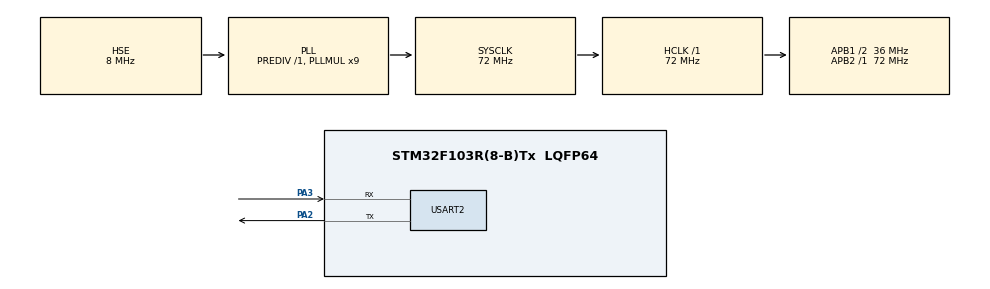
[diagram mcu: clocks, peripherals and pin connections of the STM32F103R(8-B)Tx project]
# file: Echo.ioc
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Mcu.Family=STM32F1
Mcu.Name=STM32F103R(8-B)Tx
Mcu.Package=LQFP64
NVIC.PriorityGroup=NVIC_PRIORITYGROUP_4
PA13.Mode=Serial_Wire
PA13.Signal=SYS_JTMS-SWDIO
PA14.Mode=Serial_Wire
PA14.Signal=SYS_JTCK-SWCLK
PA2.Mode=Asynchronous
PA2.Signal=USART2_TX
PA3.Mode=Asynchronous
PA3.Signal=USART2_RX
PD0-OSC_IN.Mode=HSE-External-Oscillator
PD0-OSC_IN.Signal=RCC_OSC_IN
PD1-OSC_OUT.Mode=HSE-External-Oscillator
PD1-OSC_OUT.Signal=RCC_OSC_OUT
ProjectManager.HeapSize=0x200
ProjectManager.StackSize=0x400
ProjectManager.TargetToolchain=Makefile
RCC.AHBFreq_Value=72000000
RCC.APB1CLKDivider=RCC_HCLK_DIV2
RCC.APB1Freq_Value=36000000
RCC.APB1TimFreq_Value=72000000
RCC.APB2Freq_Value=72000000
RCC.APB2TimFreq_Value=72000000
RCC.HCLKFreq_Value=72000000
RCC.PLLMUL=RCC_PLL_MUL9
RCC.PLLSourceVirtual=RCC_PLLSOURCE_HSE
RCC.SYSCLKFreq_VALUE=72000000
RCC.SYSCLKSource=RCC_SYSCLKSOURCE_PLLCLK
RCC.USBFreq_Value=72000000
USART2.VirtualMode=VM_ASYNC
board=custom

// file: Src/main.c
/* USER CODE BEGIN Header */
/**
  ******************************************************************************
  * @file           : main.c
  * @brief          : Main program body
  ******************************************************************************
  * @attention
  *
  * <h2><center>&copy; Copyright (c) 2020 STMicroelectronics.
  * All rights reserved.</center></h2>
  *
  * This software component is licensed by ST under BSD 3-Clause license,
  * the "License"; You may not use this file except in compliance with the
  * License. You may obtain a copy of the License at:
  *                        opensource.org/licenses/BSD-3-Clause
  *
  ******************************************************************************
  */
/* USER CODE END Header */
#include "main.h"
#include "usart.h"
#include "gpio.h"

/* USER CODE BEGIN Includes */
#include "string.h"
/* USER CODE END Includes */

/* USER CODE BEGIN PV */
// 用于存放接收到的字符串的字节数组
uint8_t data[80];
/* USER CODE END PV */

void SystemClock_Config(void);

int main(void)
{

  /* MCU Configuration--------------------------------------------------------*/

  /* Reset of all peripherals, Initializes the Flash interface and the Systick. */
  HAL_Init();

  /* Configure the system clock */
  SystemClock_Config();

  /* Initialize all configured peripherals */
  MX_GPIO_Init();
  MX_USART2_UART_Init();

  /* Infinite loop */
  while (1)
  {

    /* USER CODE BEGIN 3 */
    uint8_t size = 0;

    // 清空缓存�?
    memset(data, 0, 80 * sizeof(uint8_t));

    // 接收�?帧信�?
    while (data[0] == 0)                                               //直到接收到信�?
      while (HAL_UART_Receive(&huart2, data + size, 1, 100) == HAL_OK) //按时间间隔决定一帧信息的结束
        size++;

    HAL_UART_Transmit(&huart2, data, size, 1000); //原样发�?�该段信�?
  }
  /* USER CODE END 3 */
}

void SystemClock_Config(void)
{
  RCC_OscInitTypeDef RCC_OscInitStruct = {0};
  RCC_ClkInitTypeDef RCC_ClkInitStruct = {0};

  /** Initializes the RCC Oscillators according to the specified parameters
  * in the RCC_OscInitTypeDef structure.
  */
  RCC_OscInitStruct.OscillatorType = RCC_OSCILLATORTYPE_HSE;
  RCC_OscInitStruct.HSEState = RCC_HSE_ON;
  RCC_OscInitStruct.HSEPredivValue = RCC_HSE_PREDIV_DIV1;
  RCC_OscInitStruct.HSIState = RCC_HSI_ON;
  RCC_OscInitStruct.PLL.PLLState = RCC_PLL_ON;
  RCC_OscInitStruct.PLL.PLLSource = RCC_PLLSOURCE_HSE;
  RCC_OscInitStruct.PLL.PLLMUL = RCC_PLL_MUL9;
  if (HAL_RCC_OscConfig(&RCC_OscInitStruct) != HAL_OK)
  {
    Error_Handler();
  }
  /** Initializes the CPU, AHB and APB buses clocks
  */
  RCC_ClkInitStruct.ClockType = RCC_CLOCKTYPE_HCLK|RCC_CLOCKTYPE_SYSCLK
                              |RCC_CLOCKTYPE_PCLK1|RCC_CLOCKTYPE_PCLK2;
  RCC_ClkInitStruct.SYSCLKSource = RCC_SYSCLKSOURCE_PLLCLK;
  RCC_ClkInitStruct.AHBCLKDivider = RCC_SYSCLK_DIV1;
  RCC_ClkInitStruct.APB1CLKDivider = RCC_HCLK_DIV2;
  RCC_ClkInitStruct.APB2CLKDivider = RCC_HCLK_DIV1;

  if (HAL_RCC_ClockConfig(&RCC_ClkInitStruct, FLASH_LATENCY_2) != HAL_OK)
  {
    Error_Handler();
  }
}

void Error_Handler(void)
{
}

/************************ (C) COPYRIGHT STMicroelectronics *****END OF FILE****/
